# ECC_AGGR1_ECC_AGGR register map
Vendor: Texas Instruments
Peripheral module from a debugger description file (folder am243x).
Registers are 32-bit, access not given, reset 0x0 unless marked. A register's access mark holds for its fields unless they carry their own. Offsets are as the file gives them; lines under a group give offsets from that group; [hi:lo] are bit positions; {n}, {i} and the like mark numbered series; 'fields as' and 'values as' point back to an identical list; <NAME> marks a mode.

## ECC_AGGR1_ECC_AGGR
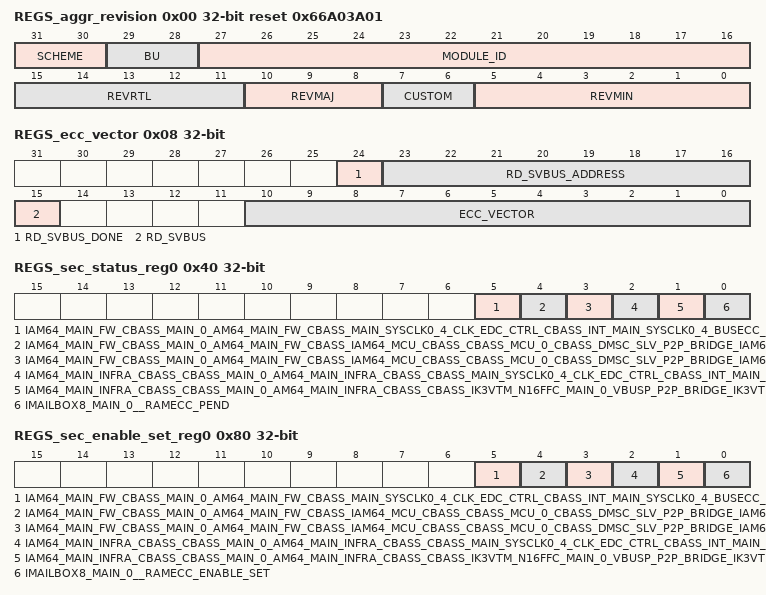
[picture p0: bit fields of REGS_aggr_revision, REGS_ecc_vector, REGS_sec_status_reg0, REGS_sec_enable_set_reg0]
0x00 REGS_aggr_revision ro reset 0x66A03A01 — Revision parameters
  [31:30] SCHEME
  [29:28] BU
  [27:16] MODULE_ID
  [15:11] REVRTL — RTL version
  [10:8] REVMAJ — Major version
  [7:6] CUSTOM — Custom version
  [5:0] REVMIN — Minor version
0x08 REGS_ecc_vector — ECC Vector Register
  [24] RD_SVBUS_DONE — Status to indicate if read on serial VBUS is complete, write of any value will clear this bit. (access R/W1TC)
  [23:16] RD_SVBUS_ADDRESS rw — Read address
  [15] RD_SVBUS — Write 1 to trigger a read on the serial VBUS (access R/W1TS)
  [10:0] ECC_VECTOR rw — Value written to select the corresponding ECC RAM for control or status
0x0C REGS_misc_status ro reset 0x6 — Misc Status
  [10:0] NUM_RAMS — Indicates the number of RAMS serviced by the ECC aggregator
0x10 REGS_reserved_svbus rw — Reference other documents that contain the ECC RAM wrapper and EDC controller serial vbus register sets.
  [31:0] DATA — Serial VBUS register data
0x3C REGS_sec_eoi_reg — EOI Register
  [0] EOI_WR — EOI Register (access R/W1TS)
0x40 REGS_sec_status_reg0 — Interrupt Status Register 0
  [5] IAM64_MAIN_FW_CBASS_MAIN_0_AM64_MAIN_FW_CBASS_MAIN_SYSCLK0_4_CLK_EDC_CTRL_CBASS_INT_MAIN_SYSCLK0_4_BUSECC_PEND — Interrupt Pending Status for Iam64_main_fw_cbass_main_0_am64_main_fw_cbass_main_SYSCLK0_4_clk_edc_ctrl_cbass_int_main_SYSCLK0_4_busecc_pend (access R/W1TS)
  [4] IAM64_MAIN_FW_CBASS_MAIN_0_AM64_MAIN_FW_CBASS_IAM64_MCU_CBASS_CBASS_MCU_0_CBASS_DMSC_SLV_P2P_BRIDGE_IAM64_MCU_CBASS_CBASS_MCU_0_CBASS_DMSC_SLV_BRIDGE_SRC_BUSECC_PEND — Interrupt Pending Status for Iam64_main_fw_cbass_main_0_am64_main_fw_cbass_Iam64_mcu_cbass_cbass_mcu_0_cbass_dmsc_slv_p2p_bridge_Iam64_mcu_cbass_cbass_mcu_0_cbass_dmsc_slv_bridge_src_busecc_pend (access R/W1TS)
  [3] IAM64_MAIN_FW_CBASS_MAIN_0_AM64_MAIN_FW_CBASS_IAM64_MCU_CBASS_CBASS_MCU_0_CBASS_DMSC_SLV_P2P_BRIDGE_IAM64_MCU_CBASS_CBASS_MCU_0_CBASS_DMSC_SLV_BRIDGE_DST_BUSECC_PEND — Interrupt Pending Status for Iam64_main_fw_cbass_main_0_am64_main_fw_cbass_Iam64_mcu_cbass_cbass_mcu_0_cbass_dmsc_slv_p2p_bridge_Iam64_mcu_cbass_cbass_mcu_0_cbass_dmsc_slv_bridge_dst_busecc_pend (access R/W1TS)
  [2] IAM64_MAIN_INFRA_CBASS_CBASS_MAIN_0_AM64_MAIN_INFRA_CBASS_CBASS_MAIN_SYSCLK0_4_CLK_EDC_CTRL_CBASS_INT_MAIN_SYSCLK0_4_BUSECC_PEND — Interrupt Pending Status for Iam64_main_infra_cbass_cbass_main_0_am64_main_infra_cbass_cbass_main_SYSCLK0_4_clk_edc_ctrl_cbass_int_main_SYSCLK0_4_busecc_pend (access R/W1TS)
  [1] IAM64_MAIN_INFRA_CBASS_CBASS_MAIN_0_AM64_MAIN_INFRA_CBASS_CBASS_IK3VTM_N16FFC_MAIN_0_VBUSP_P2P_BRIDGE_IK3VTM_N16FFC_MAIN_0_VBUSP_BRIDGE_BUSECC_PEND — Interrupt Pending Status for Iam64_main_infra_cbass_cbass_main_0_am64_main_infra_cbass_cbass_Ik3vtm_n16ffc_main_0_vbusp_p2p_bridge_Ik3vtm_n16ffc_main_0_vbusp_bridge_busecc_pend (access R/W1TS)
  [0] IMAILBOX8_MAIN_0__RAMECC_PEND — Interrupt Pending Status for Imailbox8_main_0__ramecc_pend (access R/W1TS)
0x80 REGS_sec_enable_set_reg0 — Interrupt Enable Set Register 0
  [5] IAM64_MAIN_FW_CBASS_MAIN_0_AM64_MAIN_FW_CBASS_MAIN_SYSCLK0_4_CLK_EDC_CTRL_CBASS_INT_MAIN_SYSCLK0_4_BUSECC_ENABLE_SET — Interrupt Enable Set Register for Iam64_main_fw_cbass_main_0_am64_main_fw_cbass_main_SYSCLK0_4_clk_edc_ctrl_cbass_int_main_SYSCLK0_4_busecc_pend (access R/W1TS)
  [4] IAM64_MAIN_FW_CBASS_MAIN_0_AM64_MAIN_FW_CBASS_IAM64_MCU_CBASS_CBASS_MCU_0_CBASS_DMSC_SLV_P2P_BRIDGE_IAM64_MCU_CBASS_CBASS_MCU_0_CBASS_DMSC_SLV_BRIDGE_SRC_BUSECC_ENABLE_SET — Interrupt Enable Set Register for Iam64_main_fw_cbass_main_0_am64_main_fw_cbass_Iam64_mcu_cbass_cbass_mcu_0_cbass_dmsc_slv_p2p_bridge_Iam64_mcu_cbass_cbass_mcu_0_cbass_dmsc_slv_bridge_src_busecc_pend (access R/W1TS)
  [3] IAM64_MAIN_FW_CBASS_MAIN_0_AM64_MAIN_FW_CBASS_IAM64_MCU_CBASS_CBASS_MCU_0_CBASS_DMSC_SLV_P2P_BRIDGE_IAM64_MCU_CBASS_CBASS_MCU_0_CBASS_DMSC_SLV_BRIDGE_DST_BUSECC_ENABLE_SET — Interrupt Enable Set Register for Iam64_main_fw_cbass_main_0_am64_main_fw_cbass_Iam64_mcu_cbass_cbass_mcu_0_cbass_dmsc_slv_p2p_bridge_Iam64_mcu_cbass_cbass_mcu_0_cbass_dmsc_slv_bridge_dst_busecc_pend (access R/W1TS)
  [2] IAM64_MAIN_INFRA_CBASS_CBASS_MAIN_0_AM64_MAIN_INFRA_CBASS_CBASS_MAIN_SYSCLK0_4_CLK_EDC_CTRL_CBASS_INT_MAIN_SYSCLK0_4_BUSECC_ENABLE_SET — Interrupt Enable Set Register for Iam64_main_infra_cbass_cbass_main_0_am64_main_infra_cbass_cbass_main_SYSCLK0_4_clk_edc_ctrl_cbass_int_main_SYSCLK0_4_busecc_pend (access R/W1TS)
  [1] IAM64_MAIN_INFRA_CBASS_CBASS_MAIN_0_AM64_MAIN_INFRA_CBASS_CBASS_IK3VTM_N16FFC_MAIN_0_VBUSP_P2P_BRIDGE_IK3VTM_N16FFC_MAIN_0_VBUSP_BRIDGE_BUSECC_ENABLE_SET — Interrupt Enable Set Register for Iam64_main_infra_cbass_cbass_main_0_am64_main_infra_cbass_cbass_Ik3vtm_n16ffc_main_0_vbusp_p2p_bridge_Ik3vtm_n16ffc_main_0_vbusp_bridge_busecc_pend (access R/W1TS)
  [0] IMAILBOX8_MAIN_0__RAMECC_ENABLE_SET — Interrupt Enable Set Register for Imailbox8_main_0__ramecc_pend (access R/W1TS)
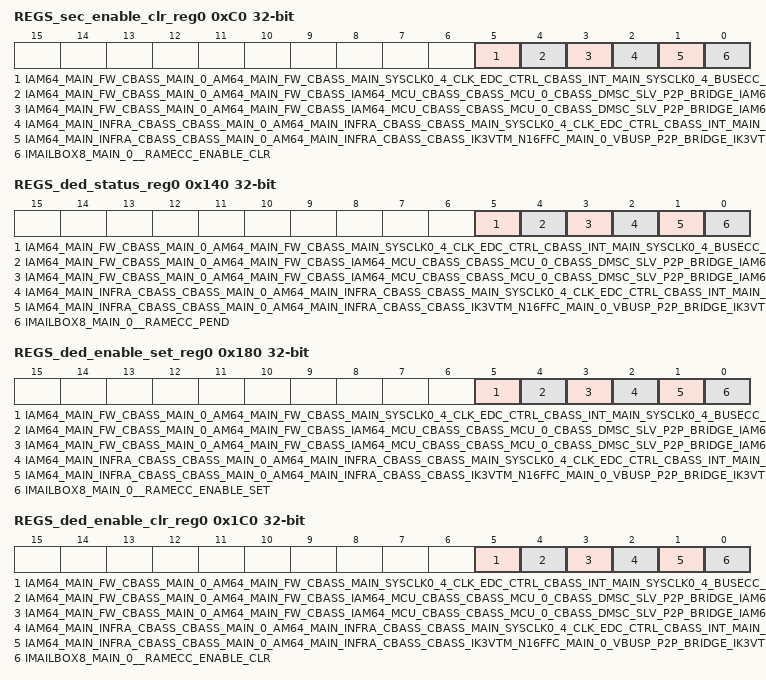
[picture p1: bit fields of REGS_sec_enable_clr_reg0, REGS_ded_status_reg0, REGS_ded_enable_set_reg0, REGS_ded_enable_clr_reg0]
0xC0 REGS_sec_enable_clr_reg0 — Interrupt Enable Clear Register 0
  [5] IAM64_MAIN_FW_CBASS_MAIN_0_AM64_MAIN_FW_CBASS_MAIN_SYSCLK0_4_CLK_EDC_CTRL_CBASS_INT_MAIN_SYSCLK0_4_BUSECC_ENABLE_CLR — Interrupt Enable Clear Register for Iam64_main_fw_cbass_main_0_am64_main_fw_cbass_main_SYSCLK0_4_clk_edc_ctrl_cbass_int_main_SYSCLK0_4_busecc_pend (access R/W1TC)
  [4] IAM64_MAIN_FW_CBASS_MAIN_0_AM64_MAIN_FW_CBASS_IAM64_MCU_CBASS_CBASS_MCU_0_CBASS_DMSC_SLV_P2P_BRIDGE_IAM64_MCU_CBASS_CBASS_MCU_0_CBASS_DMSC_SLV_BRIDGE_SRC_BUSECC_ENABLE_CLR — Interrupt Enable Clear Register for Iam64_main_fw_cbass_main_0_am64_main_fw_cbass_Iam64_mcu_cbass_cbass_mcu_0_cbass_dmsc_slv_p2p_bridge_Iam64_mcu_cbass_cbass_mcu_0_cbass_dmsc_slv_bridge_src_busecc_pend (access R/W1TC)
  [3] IAM64_MAIN_FW_CBASS_MAIN_0_AM64_MAIN_FW_CBASS_IAM64_MCU_CBASS_CBASS_MCU_0_CBASS_DMSC_SLV_P2P_BRIDGE_IAM64_MCU_CBASS_CBASS_MCU_0_CBASS_DMSC_SLV_BRIDGE_DST_BUSECC_ENABLE_CLR — Interrupt Enable Clear Register for Iam64_main_fw_cbass_main_0_am64_main_fw_cbass_Iam64_mcu_cbass_cbass_mcu_0_cbass_dmsc_slv_p2p_bridge_Iam64_mcu_cbass_cbass_mcu_0_cbass_dmsc_slv_bridge_dst_busecc_pend (access R/W1TC)
  [2] IAM64_MAIN_INFRA_CBASS_CBASS_MAIN_0_AM64_MAIN_INFRA_CBASS_CBASS_MAIN_SYSCLK0_4_CLK_EDC_CTRL_CBASS_INT_MAIN_SYSCLK0_4_BUSECC_ENABLE_CLR — Interrupt Enable Clear Register for Iam64_main_infra_cbass_cbass_main_0_am64_main_infra_cbass_cbass_main_SYSCLK0_4_clk_edc_ctrl_cbass_int_main_SYSCLK0_4_busecc_pend (access R/W1TC)
  [1] IAM64_MAIN_INFRA_CBASS_CBASS_MAIN_0_AM64_MAIN_INFRA_CBASS_CBASS_IK3VTM_N16FFC_MAIN_0_VBUSP_P2P_BRIDGE_IK3VTM_N16FFC_MAIN_0_VBUSP_BRIDGE_BUSECC_ENABLE_CLR — Interrupt Enable Clear Register for Iam64_main_infra_cbass_cbass_main_0_am64_main_infra_cbass_cbass_Ik3vtm_n16ffc_main_0_vbusp_p2p_bridge_Ik3vtm_n16ffc_main_0_vbusp_bridge_busecc_pend (access R/W1TC)
  [0] IMAILBOX8_MAIN_0__RAMECC_ENABLE_CLR — Interrupt Enable Clear Register for Imailbox8_main_0__ramecc_pend (access R/W1TC)
0x13C REGS_ded_eoi_reg — EOI Register
  [0] EOI_WR — EOI Register (access R/W1TS)
0x140 REGS_ded_status_reg0 — Interrupt Status Register 0
  fields as REGS_sec_status_reg0
0x180 REGS_ded_enable_set_reg0 — Interrupt Enable Set Register 0
  fields as REGS_sec_enable_set_reg0
0x1C0 REGS_ded_enable_clr_reg0 — Interrupt Enable Clear Register 0
  fields as REGS_sec_enable_clr_reg0
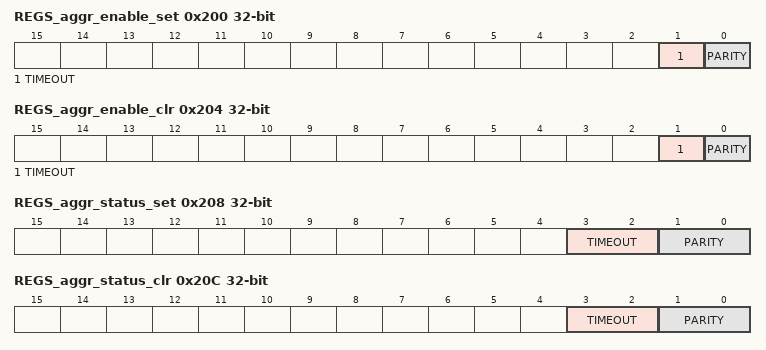
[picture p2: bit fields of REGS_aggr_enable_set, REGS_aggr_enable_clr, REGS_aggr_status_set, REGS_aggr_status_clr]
0x200 REGS_aggr_enable_set — AGGR interrupt enable set Register
  [1] TIMEOUT — interrupt enable set for svbus timeout errors (access R/W1TS)
  [0] PARITY — interrupt enable set for parity errors (access R/W1TS)
0x204 REGS_aggr_enable_clr — AGGR interrupt enable clear Register
  [1] TIMEOUT — interrupt enable clear for svbus timeout errors (access R/W1TC)
  [0] PARITY — interrupt enable clear for parity errors (access R/W1TC)
0x208 REGS_aggr_status_set — AGGR interrupt status set Register
  [3:2] TIMEOUT — interrupt status set for svbus timeout errors (access R/WI)
  [1:0] PARITY — interrupt status set for parity errors (access R/WI)
0x20C REGS_aggr_status_clr — AGGR interrupt status clear Register
  [3:2] TIMEOUT — interrupt status clear for svbus timeout errors (access R/WD)
  [1:0] PARITY — interrupt status clear for parity errors (access R/WD)
